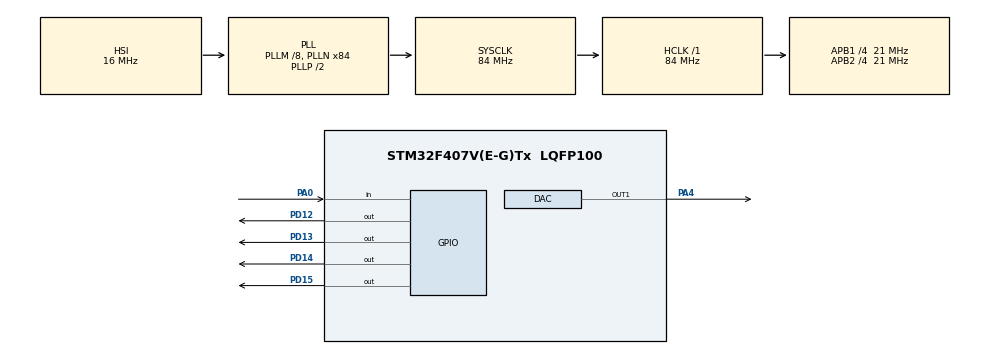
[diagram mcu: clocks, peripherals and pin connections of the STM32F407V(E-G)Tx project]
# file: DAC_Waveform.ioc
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DAC.DAC_Trigger=DAC_TRIGGER_T6_TRGO
Dma.DAC1.0.Direction=DMA_MEMORY_TO_PERIPH
Dma.DAC1.0.FIFOMode=DMA_FIFOMODE_DISABLE
Dma.DAC1.0.Instance=DMA1_Stream5
Dma.DAC1.0.MemDataAlignment=DMA_MDATAALIGN_BYTE
Dma.DAC1.0.MemInc=DMA_MINC_ENABLE
Dma.DAC1.0.Mode=DMA_CIRCULAR
Dma.DAC1.0.PeriphDataAlignment=DMA_PDATAALIGN_BYTE
Dma.DAC1.0.PeriphInc=DMA_PINC_DISABLE
Dma.DAC1.0.Priority=DMA_PRIORITY_LOW
Dma.Request0=DAC1
Mcu.Family=STM32F4
Mcu.Name=STM32F407V(E-G)Tx
Mcu.Package=LQFP100
NVIC.DMA1_Stream5_IRQn=true\:0\:0\:false\:false\:true\:false\:true
NVIC.PriorityGroup=NVIC_PRIORITYGROUP_4
PA0-WKUP.Signal=GPIO_Input
PA4.Signal=COMP_DAC1_group
PD12.Signal=GPIO_Output
PD13.Signal=GPIO_Output
PD14.Signal=GPIO_Output
PD15.Signal=GPIO_Output
PH0-OSC_IN.Mode=HSE-External-Oscillator
PH0-OSC_IN.Signal=RCC_OSC_IN
PH1-OSC_OUT.Mode=HSE-External-Oscillator
PH1-OSC_OUT.Signal=RCC_OSC_OUT
ProjectManager.HeapSize=0x200
ProjectManager.StackSize=0x400
ProjectManager.TargetToolchain=STM32CubeIDE
RCC.48MHZClocksFreq_Value=42000000
RCC.AHBFreq_Value=84000000
RCC.APB1CLKDivider=RCC_HCLK_DIV4
RCC.APB1Freq_Value=21000000
RCC.APB1TimFreq_Value=42000000
RCC.APB2CLKDivider=RCC_HCLK_DIV4
RCC.APB2Freq_Value=21000000
RCC.APB2TimFreq_Value=42000000
RCC.CortexFreq_Value=84000000
RCC.HCLKFreq_Value=84000000
RCC.HSE_VALUE=8000000
RCC.HSI_VALUE=16000000
RCC.LSE_VALUE=32768
RCC.PLLM=8
RCC.PLLN=84
RCC.SYSCLKFreq_VALUE=84000000
RCC.SYSCLKSource=RCC_SYSCLKSOURCE_PLLCLK
RCC.VCOOutputFreq_Value=168000000
SH.COMP_DAC1_group.0=DAC_OUT1,DAC_OUT1
TIM6.Period=10-1
TIM6.Prescaler=42-1
TIM6.TIM_MasterOutputTrigger=TIM_TRGO_UPDATE
VP_TIM6_VS_ClockSourceINT.Mode=Enable_Timer
board=custom

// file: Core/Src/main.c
/* USER CODE BEGIN Header */
/**
  ******************************************************************************
  * @file           : main.c
  * @brief          : Main program body
  ******************************************************************************
  * @attention
  *
  * <h2><center>&copy; Copyright (c) 2021 STMicroelectronics.
  * All rights reserved.</center></h2>
  *
  * This software component is licensed by ST under BSD 3-Clause license,
  * the "License"; You may not use this file except in compliance with the
  * License. You may obtain a copy of the License at:
  *                        opensource.org/licenses/BSD-3-Clause
  *
  ******************************************************************************
  */
/* USER CODE END Header */
#include "main.h"

DAC_HandleTypeDef hdac;
DMA_HandleTypeDef hdma_dac1;

TIM_HandleTypeDef htim6;

void SystemClock_Config(void);
static void MX_GPIO_Init(void);
static void MX_DMA_Init(void);
static void MX_DAC_Init(void);
static void MX_TIM6_Init(void);

/* USER CODE BEGIN 0 */

/* output DAC signal via DMA */
const uint8_t myDACsignal[7] ={0,40,80,120,160,200,240}; //staircase signal wave, 7 data points to be output via DMA

// then drops to 0 and resets as circular mode

/* USER CODE END 0 */

int main(void)
{

  /* MCU Configuration--------------------------------------------------------*/

  /* Reset of all peripherals, Initializes the Flash interface and the Systick. */
  HAL_Init();

  /* Configure the system clock */
  SystemClock_Config();

  /* Initialize all configured peripherals */
  MX_GPIO_Init();
  MX_DMA_Init();
  MX_DAC_Init();
  MX_TIM6_Init();
  /* USER CODE BEGIN 2 */

  //enable tim6
  HAL_TIM_Base_Start(&htim6);

//  //generate triangle wave
////  HAL_DACEx_TriangleWaveGenerate(&hdac, DAC_CHANNEL_1,DAC_TRIANGLEAMPLITUDE_2047); //channel found in the .c file, 1.5V, 24.5Hz
//  //or generate noise , comment out above
//  HAL_DACEx_NoiseWaveGenerate(&hdac, DAC_CHANNEL_1,DAC_TRIANGLEAMPLITUDE_2047);
//
//  //start DAC
//  HAL_DAC_Start(&hdac, DAC_CHANNEL_1); //start from 0
//
//  //add DC offset
//  HAL_DAC_SetValue(&hdac, DAC_CHANNEL_1, DAC_ALIGN_12B_R, 1000); //12 align right, shift right by 1V

  /* output DAC signal via DMA */
  //start DAC via DMA
  HAL_DAC_Start_DMA(&hdac,DAC_CHANNEL_1,(uint32_t*)myDACsignal, 7, DAC_ALIGN_8B_R); // circular so continuously outputs the signal, at 8 bit
  // (uint32_t *) type cast and point to start of array
  // DAC_ALIGN_8B_R will read 8bit from the start from this pointer (uint32_t *)
  /* USER CODE END 2 */

  /* Infinite loop */
  while (1)
  {

  }
}

void SystemClock_Config(void)
{
  RCC_OscInitTypeDef RCC_OscInitStruct = {0};
  RCC_ClkInitTypeDef RCC_ClkInitStruct = {0};

  /** Configure the main internal regulator output voltage
  */
  __HAL_RCC_PWR_CLK_ENABLE();
  __HAL_PWR_VOLTAGESCALING_CONFIG(PWR_REGULATOR_VOLTAGE_SCALE1);
  /** Initializes the RCC Oscillators according to the specified parameters
  * in the RCC_OscInitTypeDef structure.
  */
  RCC_OscInitStruct.OscillatorType = RCC_OSCILLATORTYPE_HSI;
  RCC_OscInitStruct.HSIState = RCC_HSI_ON;
  RCC_OscInitStruct.HSICalibrationValue = RCC_HSICALIBRATION_DEFAULT;
  RCC_OscInitStruct.PLL.PLLState = RCC_PLL_ON;
  RCC_OscInitStruct.PLL.PLLSource = RCC_PLLSOURCE_HSI;
  RCC_OscInitStruct.PLL.PLLM = 8;
  RCC_OscInitStruct.PLL.PLLN = 84;
  RCC_OscInitStruct.PLL.PLLP = RCC_PLLP_DIV2;
  RCC_OscInitStruct.PLL.PLLQ = 4;
  if (HAL_RCC_OscConfig(&RCC_OscInitStruct) != HAL_OK)
  {
    Error_Handler();
  }
  /** Initializes the CPU, AHB and APB buses clocks
  */
  RCC_ClkInitStruct.ClockType = RCC_CLOCKTYPE_HCLK|RCC_CLOCKTYPE_SYSCLK
                              |RCC_CLOCKTYPE_PCLK1|RCC_CLOCKTYPE_PCLK2;
  RCC_ClkInitStruct.SYSCLKSource = RCC_SYSCLKSOURCE_PLLCLK;
  RCC_ClkInitStruct.AHBCLKDivider = RCC_SYSCLK_DIV1;
  RCC_ClkInitStruct.APB1CLKDivider = RCC_HCLK_DIV4;
  RCC_ClkInitStruct.APB2CLKDivider = RCC_HCLK_DIV4;

  if (HAL_RCC_ClockConfig(&RCC_ClkInitStruct, FLASH_LATENCY_2) != HAL_OK)
  {
    Error_Handler();
  }
}

static void MX_DAC_Init(void)
{

  DAC_ChannelConfTypeDef sConfig = {0};

  /** DAC Initialization
  */
  hdac.Instance = DAC;
  if (HAL_DAC_Init(&hdac) != HAL_OK)
  {
    Error_Handler();
  }
  /** DAC channel OUT1 config
  */
  sConfig.DAC_Trigger = DAC_TRIGGER_T6_TRGO;
  sConfig.DAC_OutputBuffer = DAC_OUTPUTBUFFER_ENABLE;
  if (HAL_DAC_ConfigChannel(&hdac, &sConfig, DAC_CHANNEL_1) != HAL_OK)
  {
    Error_Handler();
  }

}

static void MX_TIM6_Init(void)
{

  TIM_MasterConfigTypeDef sMasterConfig = {0};

  htim6.Instance = TIM6;
  htim6.Init.Prescaler = 42-1;
  htim6.Init.CounterMode = TIM_COUNTERMODE_UP;
  htim6.Init.Period = 10-1;
  htim6.Init.AutoReloadPreload = TIM_AUTORELOAD_PRELOAD_DISABLE;
  if (HAL_TIM_Base_Init(&htim6) != HAL_OK)
  {
    Error_Handler();
  }
  sMasterConfig.MasterOutputTrigger = TIM_TRGO_UPDATE;
  sMasterConfig.MasterSlaveMode = TIM_MASTERSLAVEMODE_DISABLE;
  if (HAL_TIMEx_MasterConfigSynchronization(&htim6, &sMasterConfig) != HAL_OK)
  {
    Error_Handler();
  }

}

static void MX_DMA_Init(void)
{

  /* DMA controller clock enable */
  __HAL_RCC_DMA1_CLK_ENABLE();

  /* DMA interrupt init */
  /* DMA1_Stream5_IRQn interrupt configuration */
  HAL_NVIC_SetPriority(DMA1_Stream5_IRQn, 0, 0);
  HAL_NVIC_EnableIRQ(DMA1_Stream5_IRQn);

}

static void MX_GPIO_Init(void)
{
  GPIO_InitTypeDef GPIO_InitStruct = {0};

  /* GPIO Ports Clock Enable */
  __HAL_RCC_GPIOH_CLK_ENABLE();
  __HAL_RCC_GPIOA_CLK_ENABLE();
  __HAL_RCC_GPIOD_CLK_ENABLE();

  /*Configure GPIO pin Output Level */
  HAL_GPIO_WritePin(GPIOD, GPIO_PIN_12|GPIO_PIN_13|GPIO_PIN_14|GPIO_PIN_15, GPIO_PIN_RESET);

  /*Configure GPIO pin : PA0 */
  GPIO_InitStruct.Pin = GPIO_PIN_0;
  GPIO_InitStruct.Mode = GPIO_MODE_INPUT;
  GPIO_InitStruct.Pull = GPIO_NOPULL;
  HAL_GPIO_Init(GPIOA, &GPIO_InitStruct);

  /*Configure GPIO pins : PD12 PD13 PD14 PD15 */
  GPIO_InitStruct.Pin = GPIO_PIN_12|GPIO_PIN_13|GPIO_PIN_14|GPIO_PIN_15;
  GPIO_InitStruct.Mode = GPIO_MODE_OUTPUT_PP;
  GPIO_InitStruct.Pull = GPIO_NOPULL;
  GPIO_InitStruct.Speed = GPIO_SPEED_FREQ_LOW;
  HAL_GPIO_Init(GPIOD, &GPIO_InitStruct);

}

void Error_Handler(void)
{
  __disable_irq();
  while (1)
  {
  }
}

/************************ (C) COPYRIGHT STMicroelectronics *****END OF FILE****/
